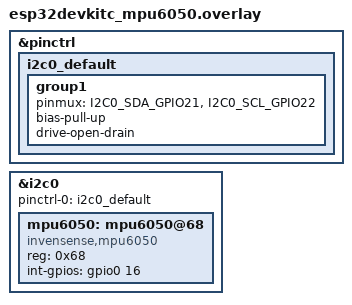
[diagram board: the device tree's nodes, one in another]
/* Configure the Pin Control for I2C0 Bus */
&pinctrl {
	i2c0_default: i2c0_default {
		group1 {
			pinmux = <I2C0_SDA_GPIO21>, <I2C0_SCL_GPIO22>;
			bias-pull-up;
			drive-open-drain;
		};
	};
};

/* Attach the MPU6050 to the actual I2C0 Controller Bus */
&i2c0 {
	status = "okay";
	pinctrl-0 = <&i2c0_default>;
	pinctrl-names = "default";

	mpu6050: mpu6050@68 {
		compatible = "invensense,mpu6050";
		reg = <0x68>; /* default MPU 6050 I2C target address it can also be configured to the address 0x69 by connecting the AD0 pin */
		int-gpios = <&gpio0 16 GPIO_ACTIVE_HIGH>;
		status = "okay";
	};
};
